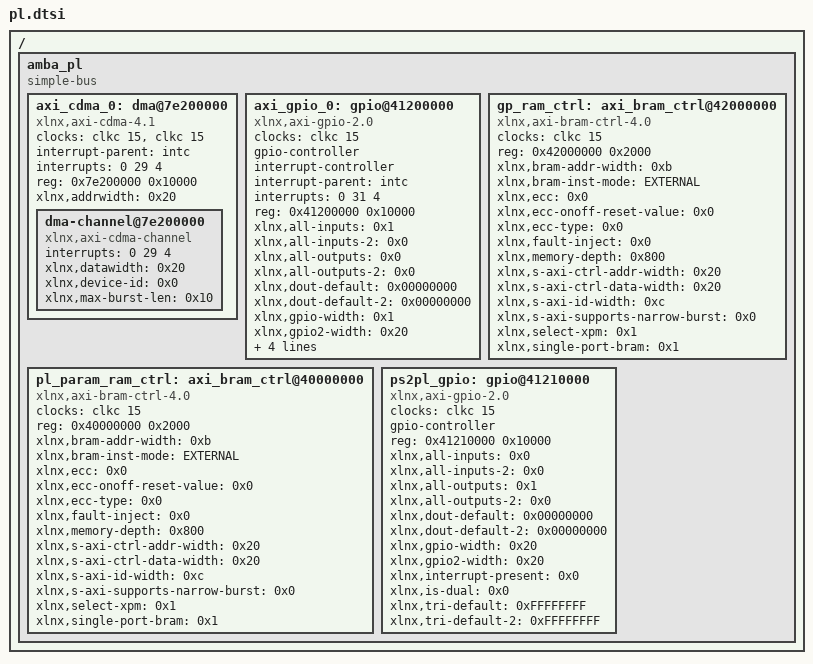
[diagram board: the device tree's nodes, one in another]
/*
 * CAUTION: This file is automatically generated by Xilinx.
 * Version:  
 * Today is: Mon Dec 24 18:30:39 2018
 */


/ {
	amba_pl: amba_pl {
		#address-cells = <1>;
		#size-cells = <1>;
		compatible = "simple-bus";
		ranges ;
		axi_cdma_0: dma@7e200000 {
			#dma-cells = <1>;
			clock-names = "m_axi_aclk s_axi_lite_aclk";
			clocks = <&clkc 15>, <&clkc 15>;
			compatible = "xlnx,axi-cdma-4.1", "xlnx,axi-cdma-1.00.a";
			interrupt-names = "cdma_introut";
			interrupt-parent = <&intc>;
			interrupts = <0 29 4>;
			reg = <0x7e200000 0x10000>;
			xlnx,addrwidth = <0x20>;
			dma-channel@7e200000 {
				compatible = "xlnx,axi-cdma-channel";
				interrupts = <0 29 4>;
				xlnx,datawidth = <0x20>;
				xlnx,device-id = <0x0>;
				xlnx,max-burst-len = <0x10>;
			};
		};
		axi_gpio_0: gpio@41200000 {
			#gpio-cells = <3>;
			#interrupt-cells = <2>;
			clock-names = "s_axi_aclk";
			clocks = <&clkc 15>;
			compatible = "xlnx,axi-gpio-2.0", "xlnx,xps-gpio-1.00.a";
			gpio-controller ;
			interrupt-controller ;
			interrupt-names = "ip2intc_irpt";
			interrupt-parent = <&intc>;
			interrupts = <0 31 4>;
			reg = <0x41200000 0x10000>;
			xlnx,all-inputs = <0x1>;
			xlnx,all-inputs-2 = <0x0>;
			xlnx,all-outputs = <0x0>;
			xlnx,all-outputs-2 = <0x0>;
			xlnx,dout-default = <0x00000000>;
			xlnx,dout-default-2 = <0x00000000>;
			xlnx,gpio-width = <0x1>;
			xlnx,gpio2-width = <0x20>;
			xlnx,interrupt-present = <0x1>;
			xlnx,is-dual = <0x0>;
			xlnx,tri-default = <0xFFFFFFFF>;
			xlnx,tri-default-2 = <0xFFFFFFFF>;
		};
		gp_ram_ctrl: axi_bram_ctrl@42000000 {
			clock-names = "s_axi_aclk";
			clocks = <&clkc 15>;
			compatible = "xlnx,axi-bram-ctrl-4.0";
			reg = <0x42000000 0x2000>;
			xlnx,bram-addr-width = <0xb>;
			xlnx,bram-inst-mode = "EXTERNAL";
			xlnx,ecc = <0x0>;
			xlnx,ecc-onoff-reset-value = <0x0>;
			xlnx,ecc-type = <0x0>;
			xlnx,fault-inject = <0x0>;
			xlnx,memory-depth = <0x800>;
			xlnx,s-axi-ctrl-addr-width = <0x20>;
			xlnx,s-axi-ctrl-data-width = <0x20>;
			xlnx,s-axi-id-width = <0xc>;
			xlnx,s-axi-supports-narrow-burst = <0x0>;
			xlnx,select-xpm = <0x1>;
			xlnx,single-port-bram = <0x1>;
		};
		pl_param_ram_ctrl: axi_bram_ctrl@40000000 {
			clock-names = "s_axi_aclk";
			clocks = <&clkc 15>;
			compatible = "xlnx,axi-bram-ctrl-4.0";
			reg = <0x40000000 0x2000>;
			xlnx,bram-addr-width = <0xb>;
			xlnx,bram-inst-mode = "EXTERNAL";
			xlnx,ecc = <0x0>;
			xlnx,ecc-onoff-reset-value = <0x0>;
			xlnx,ecc-type = <0x0>;
			xlnx,fault-inject = <0x0>;
			xlnx,memory-depth = <0x800>;
			xlnx,s-axi-ctrl-addr-width = <0x20>;
			xlnx,s-axi-ctrl-data-width = <0x20>;
			xlnx,s-axi-id-width = <0xc>;
			xlnx,s-axi-supports-narrow-burst = <0x0>;
			xlnx,select-xpm = <0x1>;
			xlnx,single-port-bram = <0x1>;
		};
		ps2pl_gpio: gpio@41210000 {
			#gpio-cells = <3>;
			clock-names = "s_axi_aclk";
			clocks = <&clkc 15>;
			compatible = "xlnx,axi-gpio-2.0", "xlnx,xps-gpio-1.00.a";
			gpio-controller ;
			reg = <0x41210000 0x10000>;
			xlnx,all-inputs = <0x0>;
			xlnx,all-inputs-2 = <0x0>;
			xlnx,all-outputs = <0x1>;
			xlnx,all-outputs-2 = <0x0>;
			xlnx,dout-default = <0x00000000>;
			xlnx,dout-default-2 = <0x00000000>;
			xlnx,gpio-width = <0x20>;
			xlnx,gpio2-width = <0x20>;
			xlnx,interrupt-present = <0x0>;
			xlnx,is-dual = <0x0>;
			xlnx,tri-default = <0xFFFFFFFF>;
			xlnx,tri-default-2 = <0xFFFFFFFF>;
		};
	};
};
